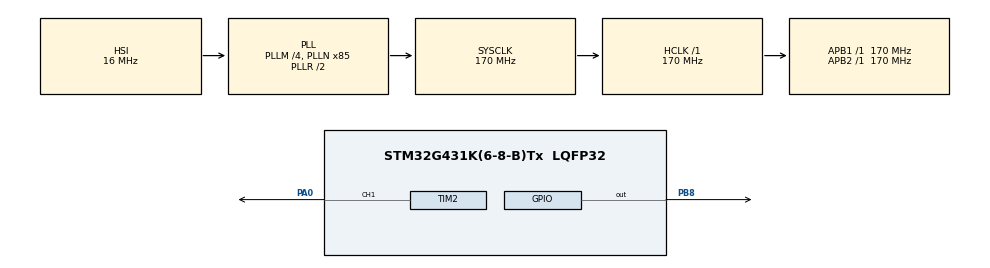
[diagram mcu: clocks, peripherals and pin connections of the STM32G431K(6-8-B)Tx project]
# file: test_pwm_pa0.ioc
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Mcu.Family=STM32G4
Mcu.Name=STM32G431K(6-8-B)Tx
Mcu.Package=LQFP32
NVIC.PriorityGroup=NVIC_PRIORITYGROUP_4
PA0.GPIO_Speed=GPIO_SPEED_FREQ_HIGH
PA0.Signal=S_TIM2_CH1
PA13.GPIO_Label=T_SWDIO
PA13.Signal=SYS_JTMS-SWDIO
PA14.GPIO_Label=T_SWCLK
PA14.Signal=SYS_JTCK-SWCLK
PA2.GPIO_Label=USART2_TX [ST-LINKV3E_VCP_RX]
PA2.Signal=USART2_TX
PA3.GPIO_Label=USART2_RX [ST-LINKV3E_VCP_TX]
PA3.Signal=USART2_RX
PB3.GPIO_Label=T_SWO
PB3.Signal=SYS_JTDO-SWO
PB8-BOOT0.Signal=GPIO_Output
ProjectManager.HeapSize=0x200
ProjectManager.StackSize=0x400
ProjectManager.TargetToolchain=STM32CubeIDE
RCC.ADC12Freq_Value=170000000
RCC.AHBFreq_Value=170000000
RCC.APB1Freq_Value=170000000
RCC.APB1TimFreq_Value=170000000
RCC.APB2Freq_Value=170000000
RCC.APB2TimFreq_Value=170000000
RCC.CortexFreq_Value=170000000
RCC.EXTERNAL_CLOCK_VALUE=12288000
RCC.HCLKFreq_Value=170000000
RCC.HSE_VALUE=8000000
RCC.HSI48_VALUE=48000000
RCC.HSI_VALUE=16000000
RCC.LSE_VALUE=32768
RCC.PLLM=RCC_PLLM_DIV4
RCC.PLLN=85
RCC.SYSCLKFreq_VALUE=170000000
RCC.SYSCLKSource=RCC_SYSCLKSOURCE_PLLCLK
RCC.USBFreq_Value=170000000
RCC.VCOOutputFreq_Value=340000000
SH.S_TIM2_CH1.0=TIM2_CH1,PWM Generation1 CH1
TIM2.Channel-PWM\ Generation1\ CH1=TIM_CHANNEL_1
TIM2.PeriodNoDither=65533
VP_SYS_VS_DBSignals.Mode=DisableDeadBatterySignals
board=NUCLEO-G431KB

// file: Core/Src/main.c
/* USER CODE BEGIN Header */
/**
  ******************************************************************************
  * @file           : main.c
  * @brief          : Main program body
  ******************************************************************************
  * @attention
  *
  * Copyright (c) 2026 STMicroelectronics.
  * All rights reserved.
  *
  * This software is licensed under terms that can be found in the LICENSE file
  * in the root directory of this software component.
  * If no LICENSE file comes with this software, it is provided AS-IS.
  *
  ******************************************************************************
  */
/* USER CODE END Header */
#include "main.h"

TIM_HandleTypeDef htim2;

void SystemClock_Config(void);
static void MX_GPIO_Init(void);
static void MX_TIM2_Init(void);

int main(void)
{

  /* MCU Configuration--------------------------------------------------------*/

  /* Reset of all peripherals, Initializes the Flash interface and the Systick. */
  HAL_Init();

  /* Configure the system clock */
  SystemClock_Config();

  /* Initialize all configured peripherals */
  MX_GPIO_Init();
  MX_TIM2_Init();
  /* USER CODE BEGIN 2 */
  HAL_TIM_PWM_Start(&htim2, TIM_CHANNEL_1);
  /* USER CODE END 2 */

  /* Infinite loop */
  while (1)
  {

    /* USER CODE BEGIN 3 */
	  HAL_Delay(1000);
	  //TIM1->CCR1 =50000;
	  TIM2->CCR1 =50000;
	  HAL_Delay(1000);
	  //TIM1->CCR1 = 10000;
	  TIM2->CCR1 = 10;
  }
  /* USER CODE END 3 */
}

void SystemClock_Config(void)
{
  RCC_OscInitTypeDef RCC_OscInitStruct = {0};
  RCC_ClkInitTypeDef RCC_ClkInitStruct = {0};

  /** Configure the main internal regulator output voltage
  */
  HAL_PWREx_ControlVoltageScaling(PWR_REGULATOR_VOLTAGE_SCALE1_BOOST);

  /** Initializes the RCC Oscillators according to the specified parameters
  * in the RCC_OscInitTypeDef structure.
  */
  RCC_OscInitStruct.OscillatorType = RCC_OSCILLATORTYPE_HSI;
  RCC_OscInitStruct.HSIState = RCC_HSI_ON;
  RCC_OscInitStruct.HSICalibrationValue = RCC_HSICALIBRATION_DEFAULT;
  RCC_OscInitStruct.PLL.PLLState = RCC_PLL_ON;
  RCC_OscInitStruct.PLL.PLLSource = RCC_PLLSOURCE_HSI;
  RCC_OscInitStruct.PLL.PLLM = RCC_PLLM_DIV4;
  RCC_OscInitStruct.PLL.PLLN = 85;
  RCC_OscInitStruct.PLL.PLLP = RCC_PLLP_DIV2;
  RCC_OscInitStruct.PLL.PLLQ = RCC_PLLQ_DIV2;
  RCC_OscInitStruct.PLL.PLLR = RCC_PLLR_DIV2;
  if (HAL_RCC_OscConfig(&RCC_OscInitStruct) != HAL_OK)
  {
    Error_Handler();
  }

  /** Initializes the CPU, AHB and APB buses clocks
  */
  RCC_ClkInitStruct.ClockType = RCC_CLOCKTYPE_HCLK|RCC_CLOCKTYPE_SYSCLK
                              |RCC_CLOCKTYPE_PCLK1|RCC_CLOCKTYPE_PCLK2;
  RCC_ClkInitStruct.SYSCLKSource = RCC_SYSCLKSOURCE_PLLCLK;
  RCC_ClkInitStruct.AHBCLKDivider = RCC_SYSCLK_DIV1;
  RCC_ClkInitStruct.APB1CLKDivider = RCC_HCLK_DIV1;
  RCC_ClkInitStruct.APB2CLKDivider = RCC_HCLK_DIV1;

  if (HAL_RCC_ClockConfig(&RCC_ClkInitStruct, FLASH_LATENCY_4) != HAL_OK)
  {
    Error_Handler();
  }
}

static void MX_TIM2_Init(void)
{

  TIM_MasterConfigTypeDef sMasterConfig = {0};
  TIM_OC_InitTypeDef sConfigOC = {0};

  htim2.Instance = TIM2;
  htim2.Init.Prescaler = 0;
  htim2.Init.CounterMode = TIM_COUNTERMODE_UP;
  htim2.Init.Period = 65533;
  htim2.Init.ClockDivision = TIM_CLOCKDIVISION_DIV1;
  htim2.Init.AutoReloadPreload = TIM_AUTORELOAD_PRELOAD_DISABLE;
  if (HAL_TIM_PWM_Init(&htim2) != HAL_OK)
  {
    Error_Handler();
  }
  sMasterConfig.MasterOutputTrigger = TIM_TRGO_RESET;
  sMasterConfig.MasterSlaveMode = TIM_MASTERSLAVEMODE_DISABLE;
  if (HAL_TIMEx_MasterConfigSynchronization(&htim2, &sMasterConfig) != HAL_OK)
  {
    Error_Handler();
  }
  sConfigOC.OCMode = TIM_OCMODE_PWM1;
  sConfigOC.Pulse = 0;
  sConfigOC.OCPolarity = TIM_OCPOLARITY_HIGH;
  sConfigOC.OCFastMode = TIM_OCFAST_DISABLE;
  if (HAL_TIM_PWM_ConfigChannel(&htim2, &sConfigOC, TIM_CHANNEL_1) != HAL_OK)
  {
    Error_Handler();
  }
  HAL_TIM_MspPostInit(&htim2);

}

static void MX_GPIO_Init(void)
{
  GPIO_InitTypeDef GPIO_InitStruct = {0};

  /* GPIO Ports Clock Enable */
  __HAL_RCC_GPIOA_CLK_ENABLE();
  __HAL_RCC_GPIOB_CLK_ENABLE();

  /*Configure GPIO pin Output Level */
  HAL_GPIO_WritePin(GPIOB, GPIO_PIN_8, GPIO_PIN_RESET);

  /*Configure GPIO pins : USART2_TX_Pin USART2_RX_Pin */
  GPIO_InitStruct.Pin = USART2_TX_Pin|USART2_RX_Pin;
  GPIO_InitStruct.Mode = GPIO_MODE_AF_PP;
  GPIO_InitStruct.Pull = GPIO_NOPULL;
  GPIO_InitStruct.Speed = GPIO_SPEED_FREQ_LOW;
  GPIO_InitStruct.Alternate = GPIO_AF7_USART2;
  HAL_GPIO_Init(GPIOA, &GPIO_InitStruct);

  /*Configure GPIO pin : PB8 */
  GPIO_InitStruct.Pin = GPIO_PIN_8;
  GPIO_InitStruct.Mode = GPIO_MODE_OUTPUT_PP;
  GPIO_InitStruct.Pull = GPIO_NOPULL;
  GPIO_InitStruct.Speed = GPIO_SPEED_FREQ_LOW;
  HAL_GPIO_Init(GPIOB, &GPIO_InitStruct);

}

void Error_Handler(void)
{
  __disable_irq();
  while (1)
  {
  }
}
